# PY32F002Axx register map
Vendor: Puya; Series: PY32F0; File version: 1.0.0
CPU: CM0+ r0p1, little endian, no MPU, no FPU, 4 interrupt priority bits
Registers are 32-bit, read-write, reset 0x0 unless marked. A register's access mark holds for its fields unless they carry their own. Offsets are from the block's base; [hi:lo] are bit positions; {n}, {i} and the like mark numbered series; 'fields as' and 'values as' point back to an identical list.

## FLASH
Base 0x40022000
0x00 ACR reset 0x600 — Access control register
  [0] LATENCY
0x08 KEYR wo — Flash key register
  [31:0] KEY — Flash key
0x0C OPTKEYR wo — Option byte key register
  [31:0] OPTKEY — Option byte key
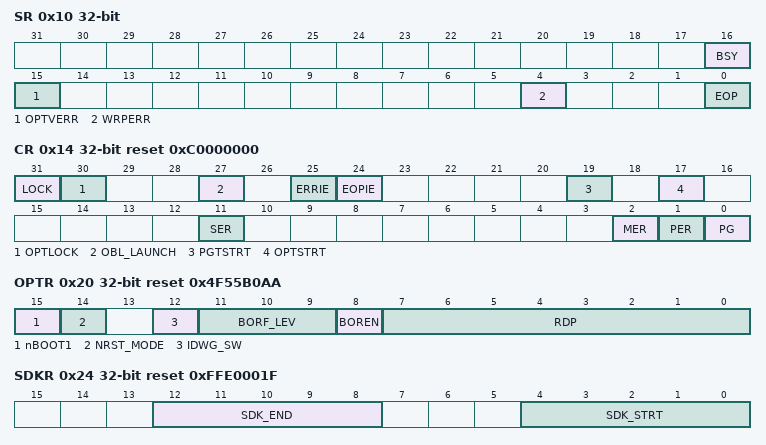
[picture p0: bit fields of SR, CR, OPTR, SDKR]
0x10 SR — Status register
  [16] BSY — Busy
  [15] OPTVERR — Option and Engineering bits loadingvalidity error
  [4] WRPERR — Write protected error
  [0] EOP — End of operation
0x14 CR reset 0xC0000000 — Flash control register
  [31] LOCK — FLASH_CR Lock
  [30] OPTLOCK — Options Lock
  [27] OBL_LAUNCH — Force the option byteloading
  [25] ERRIE — Error interrupt enable
  [24] EOPIE — End of operation interruptenable
  [19] PGTSTRT — Flash main memory program start
  [17] OPTSTRT — Option byte program start
  [11] SER — Sector erase
  [2] MER — Mass erase
  [1] PER — Page erase
  [0] PG — Programming
0x20 OPTR reset 0x4F55B0AA — Flash option register
  [15] nBOOT1 — Boot configuration
  [14] NRST_MODE
  [12] IDWG_SW — Independent watchdogselection
  [11:9] BORF_LEV — These bits contain the VDD supply levelthreshold that activates the reset
  [8] BOREN — BOR reset Level
  [7:0] RDP — Read Protection
    85=LEVEL_1; 170=LEVEL_0
0x24 SDKR reset 0xFFE0001F — Flash SDK address register
  [12:8] SDK_END — SDK area end address
    1=0; 2=1; 4=2; 8=3; 16=4
  [4:0] SDK_STRT — SDK area start address
    1=0; 2=1; 4=2; 8=3; 16=4
0x2C WRPR reset 0xFFFF — Flash WRP addressregister
  [15:0] WRP — WRP address
    1=0; 2=1; 4=2; 8=3; 16=4; 32=5; 64=6; 128=7; 0x100=8; 0x200=9; 0x400=10; 0x800=11; 0x1000=12; 0x2000=13; 0x4000=14; 0x8000=15
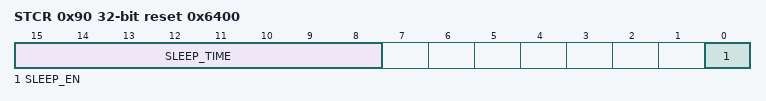
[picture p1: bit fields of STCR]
0x90 STCR reset 0x6400 — Flash sleep time configregister
  [15:8] SLEEP_TIME — FLash sleep time configuration(counter based on HSI_10M)
  [0] SLEEP_EN — FLash sleep enable
0x100 TS0 reset 0xB4 — Flash TS0 register
  [7:0] TS0 — FLash TS0 register
    1=0; 2=1; 4=2; 8=3; 16=4; 32=5; 64=6; 128=7
0x104 TS1 reset 0x1B0 — Flash TS1 register
  [8:0] TS1 — FLash TS1 register
0x108 TS2P reset 0xB4 — Flash TS2P register
  [7:0] TS2P — FLash TS2P register
    1=0; 2=1; 4=2; 8=3; 16=4; 32=5; 64=6; 128=7
0x10C TPS3 reset 0x6C0 — Flash TPS3 register
  [10:0] TPS3 — FLash TPS3 register
    1=0; 2=1; 4=2; 8=3; 16=4; 32=5; 64=6; 128=7; 0x100=8; 0x200=9; 0x400=10
0x110 TS3 reset 0xB4 — Flash TS3 register
  [7:0] TS3 — FLash TS3 register
    1=0; 2=1; 4=2; 8=3; 16=4; 32=5; 64=6; 128=7
0x114 PERTPE reset 0xEA60 — Flash PERTPE register
  [16:0] PERTPE — FLash PERTPE register
    1=0; 2=1; 4=2; 8=3; 16=4; 32=5; 64=6; 128=7; 0x100=8; 0x200=9; 0x400=10; 0x800=11; 0x1000=12; 0x2000=13; 0x4000=14; 0x8000=15; 0x10000=16
0x118 SMERTPE reset 0xFD20 — Flash SMERTPE register
  [16:0] SMERTPE — FLash SMERTPE register
    values as PERTPE.PERTPE
0x11C PRGTPE reset 0x8CA0 — Flash PRGTPE register
  [15:0] PRGTPE — FLash PRGTPE register
    values as WRPR.WRP
0x120 PRETPE reset 0x12C0 — Flash PRETPE register
  [12:0] PRETPE — FLash PRETPE register

## GPIOA — General-purpose I/Os
Base 0x50000000
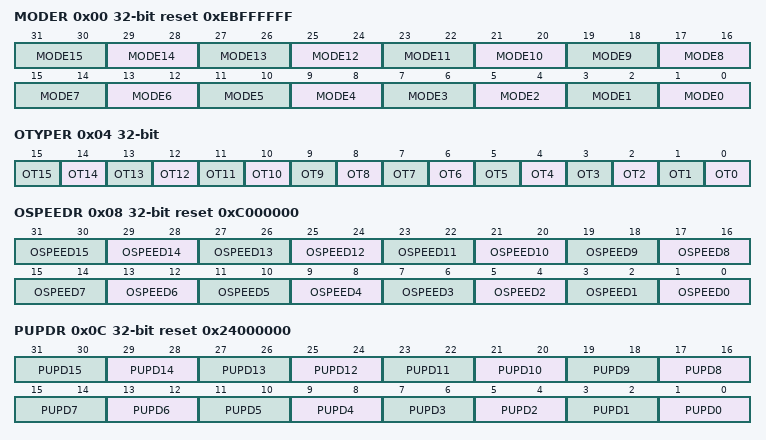
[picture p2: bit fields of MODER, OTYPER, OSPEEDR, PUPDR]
0x00 MODER reset 0xEBFFFFFF — GPIO port mode register
  [all] fields
    1=0; 2=1
  [2n+1:2n] MODE{n} (n=0..15) — Port x configuration bits (y =0..15)
0x04 OTYPER — GPIO port output type register
  [n] OT{n} (n=0..15) — Port x configuration bits (y =0..15)
0x08 OSPEEDR reset 0xC000000 — GPIO port output speedregister
  [all] fields
    1=0; 2=1
  [2n+1:2n] OSPEED{n} (n=0..15) — Port x configuration bits (y =0..15)
0x0C PUPDR reset 0x24000000 — GPIO port pull-up/pull-downregister
  [all] fields
    1=0; 2=1
  [2n+1:2n] PUPD{n} (n=0..15) — Port x configuration bits (y =0..15)
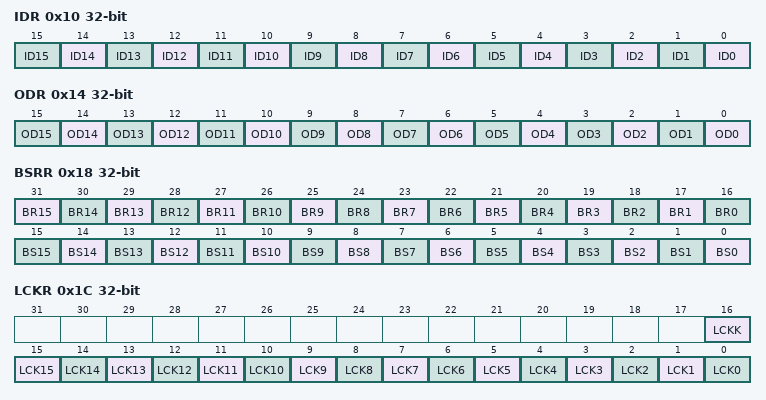
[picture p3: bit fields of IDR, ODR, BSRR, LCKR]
0x10 IDR ro — GPIO port input data register
  [n] ID{n} (n=0..15) — Port input data (y =0..15)
0x14 ODR — GPIO port output data register
  [n] OD{n} (n=0..15) — Port output data (y =0..15)
0x18 BSRR wo — GPIO port bit set/resetregister
  [n+16] BR{n} (n=1..15) — Port x reset bit y (y =0..15)
  [16] BR0 — Port x set bit y (y=0..15)
  [n] BS{n} (n=0..15) — Port x set bit y (y=0..15)
0x1C LCKR — GPIO port configuration lockregister
  [16] LCKK — Port x lock bit y (y=0..15)
  [n] LCK{n} (n=0..15) — Port x lock bit y (y=0..15)
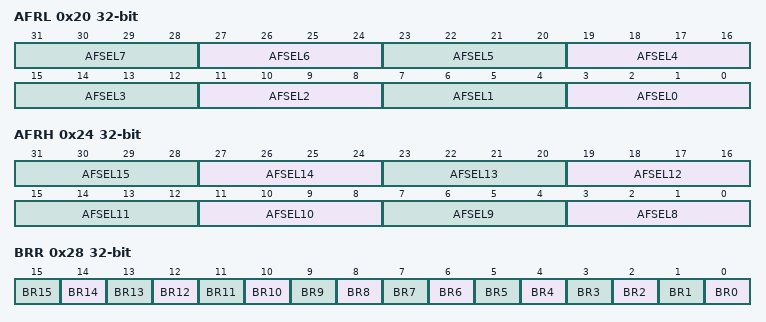
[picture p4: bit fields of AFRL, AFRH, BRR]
0x20 AFRL — GPIO alternate function lowregister
  [all] fields
    1=0; 2=1; 4=2; 8=3
  [4n+3:4n] AFSEL{n} (n=0..7) — Alternate function selection for port xbit y (y = 0..7)
0x24 AFRH — GPIO alternate function highregister
  [all] fields
    1=0; 2=1; 4=2; 8=3
  [4n-29:4n-32] AFSEL{n} (n=8..15) — Alternate function selection for port xbit y (y = 8..15)
0x28 BRR wo — port bit reset register
  [n] BR{n} (n=0..15) — Port Reset bit
